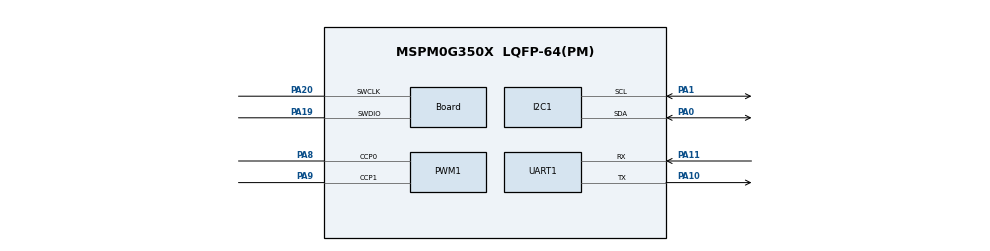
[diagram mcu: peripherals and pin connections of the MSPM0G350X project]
/**
 * @cliArgs --device "MSPM0G350X" --part "Default" --package "LQFP-64(PM)" --product "mspm0_sdk@2.05.00.05"
 * @versions {"tool":"1.24.0+4150"}
 */

/**
 * Import the modules used in this configuration.
 */
const GPIO          = scripting.addModule("/ti/driverlib/GPIO", {}, false);
const GPIO1         = GPIO.addInstance();
const GPIO2         = GPIO.addInstance();
const GPIO3         = GPIO.addInstance();
const GPIO4         = GPIO.addInstance();
const GPIO5         = GPIO.addInstance();
const GPIO6         = GPIO.addInstance();
const GPIO7         = GPIO.addInstance();
const GPIO8         = GPIO.addInstance();
const GPIO9         = GPIO.addInstance();
const I2C           = scripting.addModule("/ti/driverlib/I2C", {}, false);
const I2C1          = I2C.addInstance();
const PWM           = scripting.addModule("/ti/driverlib/PWM", {}, false);
const PWM1          = PWM.addInstance();
const SYSCTL        = scripting.addModule("/ti/driverlib/SYSCTL");
const TIMER         = scripting.addModule("/ti/driverlib/TIMER", {}, false);
const TIMER1        = TIMER.addInstance();
const UART          = scripting.addModule("/ti/driverlib/UART", {}, false);
const UART1         = UART.addInstance();
const ProjectConfig = scripting.addModule("/ti/project_config/ProjectConfig");

/**
 * Write custom configuration values to the imported modules.
 */
const gate7  = system.clockTree["MFCLKGATE"];
gate7.enable = true;

GPIO1.$name                          = "motor_L";
GPIO1.associatedPins.create(2);
GPIO1.associatedPins[0].$name        = "PB15";
GPIO1.associatedPins[0].assignedPort = "PORTB";
GPIO1.associatedPins[0].assignedPin  = "15";
GPIO1.associatedPins[1].$name        = "PB16";
GPIO1.associatedPins[1].assignedPort = "PORTB";
GPIO1.associatedPins[1].assignedPin  = "16";

const Board                       = scripting.addModule("/ti/driverlib/Board", {}, false);
Board.peripheral.$assign          = "DEBUGSS";
Board.peripheral.swclkPin.$assign = "PA20";
Board.peripheral.swdioPin.$assign = "PA19";

GPIO2.$name                          = "motor_R";
GPIO2.associatedPins.create(2);
GPIO2.associatedPins[0].$name        = "PB2";
GPIO2.associatedPins[0].assignedPin  = "2";
GPIO2.associatedPins[0].assignedPort = "PORTB";
GPIO2.associatedPins[1].$name        = "PB3";
GPIO2.associatedPins[1].assignedPort = "PORTB";
GPIO2.associatedPins[1].assignedPin  = "3";

GPIO3.$name                               = "encoder_L";
GPIO3.associatedPins.create(2);
GPIO3.associatedPins[0].$name             = "PB6";
GPIO3.associatedPins[0].direction         = "INPUT";
GPIO3.associatedPins[0].assignedPort      = "PORTB";
GPIO3.associatedPins[0].assignedPin       = "6";
GPIO3.associatedPins[0].interruptEn       = true;
GPIO3.associatedPins[0].interruptPriority = "0";
GPIO3.associatedPins[0].polarity          = "RISE_FALL";
GPIO3.associatedPins[1].$name             = "PB7";
GPIO3.associatedPins[1].direction         = "INPUT";
GPIO3.associatedPins[1].assignedPort      = "PORTB";
GPIO3.associatedPins[1].assignedPin       = "7";
GPIO3.associatedPins[1].interruptEn       = true;
GPIO3.associatedPins[1].interruptPriority = "0";
GPIO3.associatedPins[1].polarity          = "RISE_FALL";

GPIO4.$name                               = "encoder_R";
GPIO4.associatedPins.create(2);
GPIO4.associatedPins[0].$name             = "PB8";
GPIO4.associatedPins[0].direction         = "INPUT";
GPIO4.associatedPins[0].assignedPort      = "PORTB";
GPIO4.associatedPins[0].assignedPin       = "8";
GPIO4.associatedPins[0].interruptEn       = true;
GPIO4.associatedPins[0].interruptPriority = "0";
GPIO4.associatedPins[0].polarity          = "RISE_FALL";
GPIO4.associatedPins[1].$name             = "PB9";
GPIO4.associatedPins[1].direction         = "INPUT";
GPIO4.associatedPins[1].assignedPort      = "PORTB";
GPIO4.associatedPins[1].assignedPin       = "9";
GPIO4.associatedPins[1].interruptEn       = true;
GPIO4.associatedPins[1].interruptPriority = "0";
GPIO4.associatedPins[1].polarity          = "RISE_FALL";

GPIO5.$name                              = "tracing";
GPIO5.associatedPins.create(7);
GPIO5.associatedPins[0].$name            = "PA14";
GPIO5.associatedPins[0].direction        = "INPUT";
GPIO5.associatedPins[0].internalResistor = "PULL_UP";
GPIO5.associatedPins[0].assignedPort     = "PORTA";
GPIO5.associatedPins[0].assignedPin      = "14";
GPIO5.associatedPins[1].$name            = "PA15";
GPIO5.associatedPins[1].direction        = "INPUT";
GPIO5.associatedPins[1].assignedPort     = "PORTA";
GPIO5.associatedPins[1].assignedPin      = "15";
GPIO5.associatedPins[1].internalResistor = "PULL_UP";
GPIO5.associatedPins[2].$name            = "PA16";
GPIO5.associatedPins[2].direction        = "INPUT";
GPIO5.associatedPins[2].internalResistor = "PULL_UP";
GPIO5.associatedPins[2].assignedPort     = "PORTA";
GPIO5.associatedPins[2].assignedPin      = "16";
GPIO5.associatedPins[3].$name            = "PA17";
GPIO5.associatedPins[3].direction        = "INPUT";
GPIO5.associatedPins[3].assignedPort     = "PORTA";
GPIO5.associatedPins[3].assignedPin      = "17";
GPIO5.associatedPins[3].internalResistor = "PULL_UP";
GPIO5.associatedPins[4].$name            = "PA22";
GPIO5.associatedPins[4].direction        = "INPUT";
GPIO5.associatedPins[4].assignedPort     = "PORTA";
GPIO5.associatedPins[4].assignedPin      = "22";
GPIO5.associatedPins[4].internalResistor = "PULL_UP";
GPIO5.associatedPins[5].$name            = "PB18";
GPIO5.associatedPins[5].direction        = "INPUT";
GPIO5.associatedPins[5].internalResistor = "PULL_UP";
GPIO5.associatedPins[5].assignedPort     = "PORTB";
GPIO5.associatedPins[5].assignedPin      = "18";
GPIO5.associatedPins[6].$name            = "PB17";
GPIO5.associatedPins[6].direction        = "INPUT";
GPIO5.associatedPins[6].internalResistor = "PULL_UP";
GPIO5.associatedPins[6].assignedPort     = "PORTB";
GPIO5.associatedPins[6].assignedPin      = "17";

GPIO6.$name                              = "ICM42688";
GPIO6.associatedPins.create(4);
GPIO6.associatedPins[0].$name            = "PIN_0";
GPIO6.associatedPins[0].assignedPort     = "PORTA";
GPIO6.associatedPins[0].assignedPin      = "24";
GPIO6.associatedPins[0].internalResistor = "PULL_UP";
GPIO6.associatedPins[1].$name            = "PIN_1";
GPIO6.associatedPins[1].assignedPort     = "PORTA";
GPIO6.associatedPins[1].assignedPin      = "25";
GPIO6.associatedPins[1].internalResistor = "PULL_UP";
GPIO6.associatedPins[2].$name            = "PIN_2";
GPIO6.associatedPins[2].internalResistor = "PULL_UP";
GPIO6.associatedPins[2].assignedPort     = "PORTA";
GPIO6.associatedPins[2].assignedPin      = "26";
GPIO6.associatedPins[3].$name            = "PIN_3";
GPIO6.associatedPins[3].assignedPort     = "PORTA";
GPIO6.associatedPins[3].assignedPin      = "27";
GPIO6.associatedPins[3].internalResistor = "PULL_UP";
GPIO6.associatedPins[3].direction        = "INPUT";

GPIO7.$name                              = "BEEP";
GPIO7.associatedPins[0].$name            = "PIN_4";
GPIO7.associatedPins[0].assignedPort     = "PORTB";
GPIO7.associatedPins[0].assignedPin      = "0";
GPIO7.associatedPins[0].internalResistor = "PULL_DOWN";

GPIO8.$name                              = "KEY";
GPIO8.associatedPins.create(3);
GPIO8.associatedPins[0].$name            = "PB1";
GPIO8.associatedPins[0].direction        = "INPUT";
GPIO8.associatedPins[0].assignedPort     = "PORTB";
GPIO8.associatedPins[0].assignedPin      = "1";
GPIO8.associatedPins[0].internalResistor = "PULL_UP";
GPIO8.associatedPins[1].$name            = "PB11";
GPIO8.associatedPins[1].direction        = "INPUT";
GPIO8.associatedPins[1].internalResistor = "PULL_UP";
GPIO8.associatedPins[1].assignedPort     = "PORTB";
GPIO8.associatedPins[1].assignedPin      = "11";
GPIO8.associatedPins[2].$name            = "PB14";
GPIO8.associatedPins[2].direction        = "INPUT";
GPIO8.associatedPins[2].assignedPort     = "PORTB";
GPIO8.associatedPins[2].assignedPin      = "14";
GPIO8.associatedPins[2].internalResistor = "PULL_UP";

GPIO9.$name                          = "LED";
GPIO9.associatedPins.create(2);
GPIO9.associatedPins[0].$name        = "PB21";
GPIO9.associatedPins[0].assignedPort = "PORTB";
GPIO9.associatedPins[0].assignedPin  = "21";
GPIO9.associatedPins[1].$name        = "PB22";
GPIO9.associatedPins[1].assignedPort = "PORTB";
GPIO9.associatedPins[1].assignedPin  = "22";

I2C1.$name                     = "I2C_0";
I2C1.basicEnableController     = true;
I2C1.basicClockSourceDivider   = 4;
I2C1.peripheral.$assign        = "I2C0";
I2C1.peripheral.sdaPin.$assign = "PA0";
I2C1.peripheral.sclPin.$assign = "PA1";
I2C1.sdaPinConfig.$name        = "ti_driverlib_gpio_GPIOPinGeneric4";
I2C1.sclPinConfig.$name        = "ti_driverlib_gpio_GPIOPinGeneric5";

PWM1.$name                      = "PWM_0";
PWM1.timerStartTimer            = true;
PWM1.pwmMode                    = "EDGE_ALIGN_UP";
PWM1.timerCount                 = 800;
PWM1.clockDivider               = 2;
PWM1.peripheral.$assign         = "TIMA0";
PWM1.peripheral.ccp0Pin.$assign = "PA8";
PWM1.peripheral.ccp1Pin.$assign = "PA9";
PWM1.PWM_CHANNEL_0.$name        = "ti_driverlib_pwm_PWMTimerCC0";
PWM1.PWM_CHANNEL_1.$name        = "ti_driverlib_pwm_PWMTimerCC1";
PWM1.ccp0PinConfig.$name        = "ti_driverlib_gpio_GPIOPinGeneric0";
PWM1.ccp1PinConfig.$name        = "ti_driverlib_gpio_GPIOPinGeneric1";

SYSCTL.forceDefaultClkConfig = true;
SYSCTL.clockTreeEn           = true;

TIMER1.$name              = "TIMG12";
TIMER1.interrupts         = ["ZERO"];
TIMER1.timerStartTimer    = true;
TIMER1.timerClkDiv        = 8;
TIMER1.timerMode          = "PERIODIC";
TIMER1.interruptPriority  = "1";
TIMER1.timerPeriod        = "50ms";
TIMER1.peripheral.$assign = "TIMG12";

UART1.$name                    = "UART_0";
UART1.uartClkSrc               = "MFCLK";
UART1.enabledInterrupts        = ["RX"];
UART1.peripheral.$assign       = "UART0";
UART1.peripheral.rxPin.$assign = "PA11";
UART1.peripheral.txPin.$assign = "PA10";
UART1.txPinConfig.$name        = "ti_driverlib_gpio_GPIOPinGeneric2";
UART1.rxPinConfig.$name        = "ti_driverlib_gpio_GPIOPinGeneric3";

ProjectConfig.deviceSpin = "MSPM0G3507";

/**
 * Pinmux solution for unlocked pins/peripherals. This ensures that minor changes to the automatic solver in a future
 * version of the tool will not impact the pinmux you originally saw.  These lines can be completely deleted in order to
 * re-solve from scratch.
 */
GPIO1.associatedPins[0].pin.$suggestSolution = "PB15";
GPIO1.associatedPins[1].pin.$suggestSolution = "PB16";
GPIO2.associatedPins[0].pin.$suggestSolution = "PB2";
GPIO2.associatedPins[1].pin.$suggestSolution = "PB3";
GPIO3.associatedPins[0].pin.$suggestSolution = "PB6";
GPIO3.associatedPins[1].pin.$suggestSolution = "PB7";
GPIO4.associatedPins[0].pin.$suggestSolution = "PB8";
GPIO4.associatedPins[1].pin.$suggestSolution = "PB9";
GPIO5.associatedPins[0].pin.$suggestSolution = "PA14";
GPIO5.associatedPins[1].pin.$suggestSolution = "PA15";
GPIO5.associatedPins[2].pin.$suggestSolution = "PA16";
GPIO5.associatedPins[3].pin.$suggestSolution = "PA17";
GPIO5.associatedPins[4].pin.$suggestSolution = "PA22";
GPIO5.associatedPins[5].pin.$suggestSolution = "PB18";
GPIO5.associatedPins[6].pin.$suggestSolution = "PB17";
GPIO6.associatedPins[0].pin.$suggestSolution = "PA24";
GPIO6.associatedPins[1].pin.$suggestSolution = "PA25";
GPIO6.associatedPins[2].pin.$suggestSolution = "PA26";
GPIO6.associatedPins[3].pin.$suggestSolution = "PA27";
GPIO7.associatedPins[0].pin.$suggestSolution = "PB0";
GPIO8.associatedPins[0].pin.$suggestSolution = "PB1";
GPIO8.associatedPins[1].pin.$suggestSolution = "PB11";
GPIO8.associatedPins[2].pin.$suggestSolution = "PB14";
GPIO9.associatedPins[0].pin.$suggestSolution = "PB21";
GPIO9.associatedPins[1].pin.$suggestSolution = "PB22";
